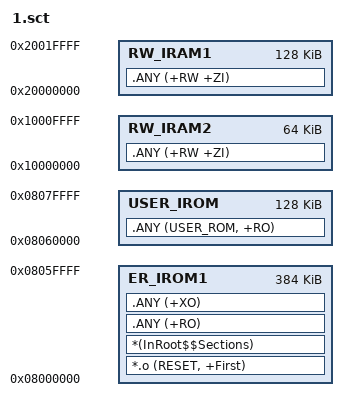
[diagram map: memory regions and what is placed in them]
; *************************************************************
; *** Scatter-Loading Description File generated by uVision ***
; *************************************************************
 
; load region size_region
LR_IROM1 0x08000000 0x00060000  
{   
  ; load address = execution address
  ER_IROM1 0x08000000 0x00060000 
  {  
   *.o (RESET, +First)
   *(InRoot$$Sections)
   .ANY (+RO)
   .ANY (+XO)
  }

  ; RW data
  RW_IRAM1 0x20000000 0x00020000  
  { 
   .ANY (+RW +ZI)
  }
  RW_IRAM2 0x10000000 0x00010000  
  {
   .ANY (+RW +ZI)
  }
}

;必须单独再开一个加载域，使加载域与其中的执行域地址相等
LR_IROM2 0x08060000 0x00020000 
{  
  USER_IROM 0x08060000 0x00020000 
  {  
    .ANY (USER_ROM, +RO)
  }
}

